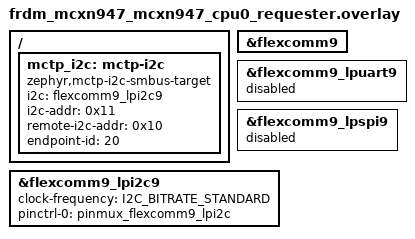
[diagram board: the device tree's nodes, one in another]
/*
 * Copyright 2026 NXP
 * SPDX-License-Identifier: Apache-2.0
 */

/ {
	mctp_i2c: mctp-i2c {
		compatible = "zephyr,mctp-i2c-smbus-target";
		i2c = <&flexcomm9_lpi2c9>;
		i2c-addr = <0x11>;
		remote-i2c-addr = <0x10>;
		endpoint-id = <20>;
	};
};

&flexcomm9 {
	status = "okay";
};

&flexcomm9_lpuart9 {
	status = "disabled";
};

&flexcomm9_lpspi9 {
	status = "disabled";
};

&flexcomm9_lpi2c9 {
	status = "okay";
	clock-frequency = <I2C_BITRATE_STANDARD>;
	pinctrl-0 = <&pinmux_flexcomm9_lpi2c>;
	pinctrl-names = "default";
};
